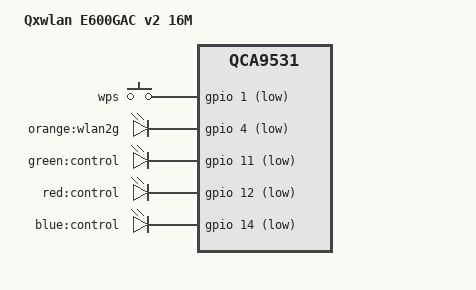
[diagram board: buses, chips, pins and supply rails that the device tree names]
// SPDX-License-Identifier: GPL-2.0-or-later OR MIT

#include "qca9531_qxwlan_e600g.dtsi"

/ {
	model = "Qxwlan E600GAC v2 16M";
	compatible = "qxwlan,e600gac-v2-16m", "qca,qca9531";
};

&keys {
	wps {
		label = "wps";
		linux,code = <KEY_WPS_BUTTON>;
		gpios = <&gpio 1 GPIO_ACTIVE_LOW>;
		debounce-interval = <60>;
	};
};

&leds {
	wlan2g {
		label = "orange:wlan2g";
		gpios = <&gpio 4 GPIO_ACTIVE_LOW>;
		linux,default-trigger = "phy1tpt";
	};

	control1 {
		label = "green:control";
		gpios = <&gpio 11 GPIO_ACTIVE_LOW>;
	};

	control2 {
		label = "red:control";
		gpios = <&gpio 12 GPIO_ACTIVE_LOW>;
	};

	control3 {
		label = "blue:control";
		gpios = <&gpio 14 GPIO_ACTIVE_LOW>;
	};
};

&partitions {
	partition@70000 {
		compatible = "denx,uimage";
		label = "firmware";
		reg = <0x070000 0xf90000>;
	};
};
